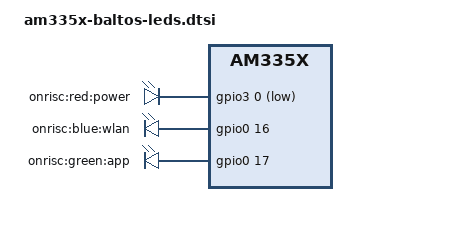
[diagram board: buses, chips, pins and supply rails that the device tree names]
/ {
	leds {
		pinctrl-names = "default";
		pinctrl-0 = <&user_leds>;
		compatible = "gpio-leds";
		led-power {
			label = "onrisc:red:power";
			linux,default-trigger = "default-on";
			gpios = <&gpio3 0 GPIO_ACTIVE_LOW>;
			default-state = "on";
		};
		led-wlan {
			label = "onrisc:blue:wlan";
			gpios = <&gpio0 16 GPIO_ACTIVE_HIGH>;
			default-state = "off";
		};
		led-app {
			label = "onrisc:green:app";
			gpios = <&gpio0 17 GPIO_ACTIVE_HIGH>;
			default-state = "off";
		};
	};
};
&am33xx_pinmux {
	user_leds: user-leds-pins {
		pinctrl-single,pins = <
			AM33XX_PADCONF(AM335X_PIN_MII1_COL, PIN_OUTPUT_PULLDOWN, MUX_MODE7)	 
			AM33XX_PADCONF(AM335X_PIN_MII1_TXD3, PIN_OUTPUT_PULLDOWN, MUX_MODE7)	 
			AM33XX_PADCONF(AM335X_PIN_MII1_TXD2, PIN_OUTPUT_PULLDOWN, MUX_MODE7)	 
		>;
	};
};
